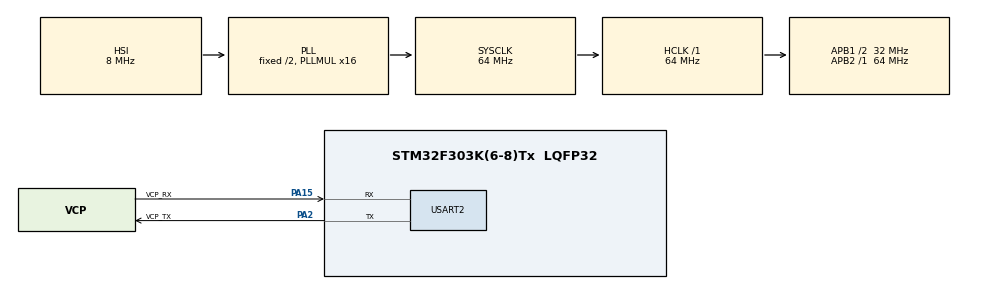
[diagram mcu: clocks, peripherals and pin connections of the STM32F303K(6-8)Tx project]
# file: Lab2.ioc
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Mcu.Family=STM32F3
Mcu.Name=STM32F303K(6-8)Tx
Mcu.Package=LQFP32
NVIC.PriorityGroup=NVIC_PRIORITYGROUP_4
PA13.GPIO_Label=SWDIO
PA13.Mode=Serial_Wire
PA13.Signal=SYS_JTMS-SWDIO
PA14.GPIO_Label=SWCLK
PA14.Mode=Serial_Wire
PA14.Signal=SYS_JTCK-SWCLK
PA15.GPIO_Label=VCP_RX
PA15.Mode=Asynchronous
PA15.Signal=USART2_RX
PA2.GPIO_Label=VCP_TX
PA2.Mode=Asynchronous
PA2.Signal=USART2_TX
PF0\ /\ OSC_IN.GPIO_Label=MCO
PF0\ /\ OSC_IN.Mode=HSE-External-Clock-Source
PF0\ /\ OSC_IN.Signal=RCC_OSC_IN
ProjectManager.HeapSize=0x200
ProjectManager.StackSize=0x400
ProjectManager.TargetToolchain=STM32CubeIDE
RCC.AHBFreq_Value=64000000
RCC.APB1CLKDivider=RCC_HCLK_DIV2
RCC.APB1Freq_Value=32000000
RCC.APB1TimFreq_Value=64000000
RCC.APB2Freq_Value=64000000
RCC.APB2TimFreq_Value=64000000
RCC.CortexFreq_Value=64000000
RCC.HCLKFreq_Value=64000000
RCC.HSE_VALUE=8000000
RCC.HSI_VALUE=8000000
RCC.PLLMUL=RCC_PLL_MUL16
RCC.SYSCLKFreq_VALUE=64000000
RCC.SYSCLKSourceVirtual=RCC_SYSCLKSOURCE_PLLCLK
USART2.VirtualMode-Asynchronous=VM_ASYNC
board=NUCLEO-F303K8

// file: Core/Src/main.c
/* USER CODE BEGIN Header */
/**
  ******************************************************************************
  * @file           : main.c
  * @brief          : Main program body
  ******************************************************************************
  * @attention
  *
  * Copyright (c) 2023 STMicroelectronics.
  * All rights reserved.
  *
  * This software is licensed under terms that can be found in the LICENSE file
  * in the root directory of this software component.
  * If no LICENSE file comes with this software, it is provided AS-IS.
  *
  ******************************************************************************
  */
/* USER CODE END Header */
#include "main.h"
// Define the bit to be set
const unsigned char seq[] ={8 ,0x0C ,4 ,6,2 ,3 ,1 ,9};
// Define the bit to be reset, i,e. complement of seq with a mask
// on the 4 least significan bits
const unsigned char seqAND[]={7 , 3 ,11 ,9 ,13 ,12 ,14 ,6};
int8_t step;

/* USER CODE BEGIN Includes */
void setup()
{
	//Question 1:

	//Enable clock for Port A
	RCC->AHBENR |= (0x1<<17);
	__asm (" nop");

	// Config PA5 to PA8 as output
	// First reset by putting "00"
	  GPIOA->MODER &= ~((0x03<<10) | (0x03<<12) | (0x03<<14) | (0x03<<16));
    // Secondly, put "01" to set as output
	  GPIOA->MODER |= (0x01<<10) | (0x01<<12) | (0x01<<14) | (0x01<<16);

	 //Question 3:

	  // use TIM6@10Hz
	  // input clock = 64 MHz.
	  // TIM6 timer clock enable
	   RCC -> APB1ENR |= 0x01<<4 ;
	   __asm (" nop");

	   // reset peripheral ( mandatory !)
	   RCC -> APB1RSTR |= 0x01<<4 ;
	   RCC -> APB1RSTR &= ~(0x01<<4) ;
	   __asm (" nop");

	   // 64MHz/64000=64.10^6/64.10^3=10^3 => tick@1ms
	   // 100 tick at 1ms => total time = 100ms <=> 10Hz
	   TIM6 -> PSC = 64000 -1; // prescaler : tick@1ms
	   TIM6 -> ARR = 100 -1;
	   TIM6 -> CR1 |= 0x01<<0 ; // enable
}
	   void stepCCW(int8_t i)
	   {
	     // << 5 because PA5 to PA8
	     // Add a mask so as not to set the other bits to 0 except bits 5 to 8!

	     GPIOA->ODR = (GPIOA->ODR | seq[i] << 5) & ~((~seq[i] & 0x0F) << 5);

	     // or
	     //GPIOA->ODR = (GPIOA->ODR | seq[i] << 5) & ~(seqAND[i] << 5);
	     //GPIOA->ODR |= (seq[i] << 5) & ~((~seq[i] & 0x0F) << 5);

	     //Question 4:
	     //GPIOA->BSRR = (seq[i]<<5)| ((~seq[i]& 0x0F)<<(5+16));

	   }

/* USER CODE END Includes */

UART_HandleTypeDef huart2;

void SystemClock_Config(void);
static void MX_GPIO_Init(void);
static void MX_USART2_UART_Init(void);

int main(void)
{
  /* USER CODE BEGIN 1 */

	 // Put as output PA5 to PA8
	  setup();
	  step = 0;
	  stepCCW(step);
  /* USER CODE END 1 */

  /* MCU Configuration--------------------------------------------------------*/

  /* Reset of all peripherals, Initializes the Flash interface and the Systick. */
  HAL_Init();

  /* Configure the system clock */
  SystemClock_Config();

  /* Initialize all configured peripherals */
  MX_GPIO_Init();
  MX_USART2_UART_Init();

  /* Infinite loop */
  while (1)
  {
	    if(TIM6->SR & (0x1<<0) // overflow ?
	    {
	      TIM6->SR &= ~(0x1<<0); // reset overflow flag
	      step = (step+1)%8;
	      stepCCW(step);

  }
}

void SystemClock_Config(void)
{
  RCC_OscInitTypeDef RCC_OscInitStruct = {0};
  RCC_ClkInitTypeDef RCC_ClkInitStruct = {0};

  /** Initializes the RCC Oscillators according to the specified parameters
  * in the RCC_OscInitTypeDef structure.
  */
  RCC_OscInitStruct.OscillatorType = RCC_OSCILLATORTYPE_HSI;
  RCC_OscInitStruct.HSIState = RCC_HSI_ON;
  RCC_OscInitStruct.HSICalibrationValue = RCC_HSICALIBRATION_DEFAULT;
  RCC_OscInitStruct.PLL.PLLState = RCC_PLL_ON;
  RCC_OscInitStruct.PLL.PLLSource = RCC_PLLSOURCE_HSI;
  RCC_OscInitStruct.PLL.PLLMUL = RCC_PLL_MUL16;
  if (HAL_RCC_OscConfig(&RCC_OscInitStruct) != HAL_OK)
  {
    Error_Handler();
  }

  /** Initializes the CPU, AHB and APB buses clocks
  */
  RCC_ClkInitStruct.ClockType = RCC_CLOCKTYPE_HCLK|RCC_CLOCKTYPE_SYSCLK
                              |RCC_CLOCKTYPE_PCLK1|RCC_CLOCKTYPE_PCLK2;
  RCC_ClkInitStruct.SYSCLKSource = RCC_SYSCLKSOURCE_PLLCLK;
  RCC_ClkInitStruct.AHBCLKDivider = RCC_SYSCLK_DIV1;
  RCC_ClkInitStruct.APB1CLKDivider = RCC_HCLK_DIV2;
  RCC_ClkInitStruct.APB2CLKDivider = RCC_HCLK_DIV1;

  if (HAL_RCC_ClockConfig(&RCC_ClkInitStruct, FLASH_LATENCY_2) != HAL_OK)
  {
    Error_Handler();
  }
}

static void MX_USART2_UART_Init(void)
{

  huart2.Instance = USART2;
  huart2.Init.BaudRate = 38400;
  huart2.Init.WordLength = UART_WORDLENGTH_8B;
  huart2.Init.StopBits = UART_STOPBITS_1;
  huart2.Init.Parity = UART_PARITY_NONE;
  huart2.Init.Mode = UART_MODE_TX_RX;
  huart2.Init.HwFlowCtl = UART_HWCONTROL_NONE;
  huart2.Init.OverSampling = UART_OVERSAMPLING_16;
  huart2.Init.OneBitSampling = UART_ONE_BIT_SAMPLE_DISABLE;
  huart2.AdvancedInit.AdvFeatureInit = UART_ADVFEATURE_NO_INIT;
  if (HAL_UART_Init(&huart2) != HAL_OK)
  {
    Error_Handler();
  }

}

static void MX_GPIO_Init(void)
{

  /* GPIO Ports Clock Enable */
  __HAL_RCC_GPIOF_CLK_ENABLE();
  __HAL_RCC_GPIOA_CLK_ENABLE();

}

void Error_Handler(void)
{
  __disable_irq();
  while (1)
  {
  }
}
